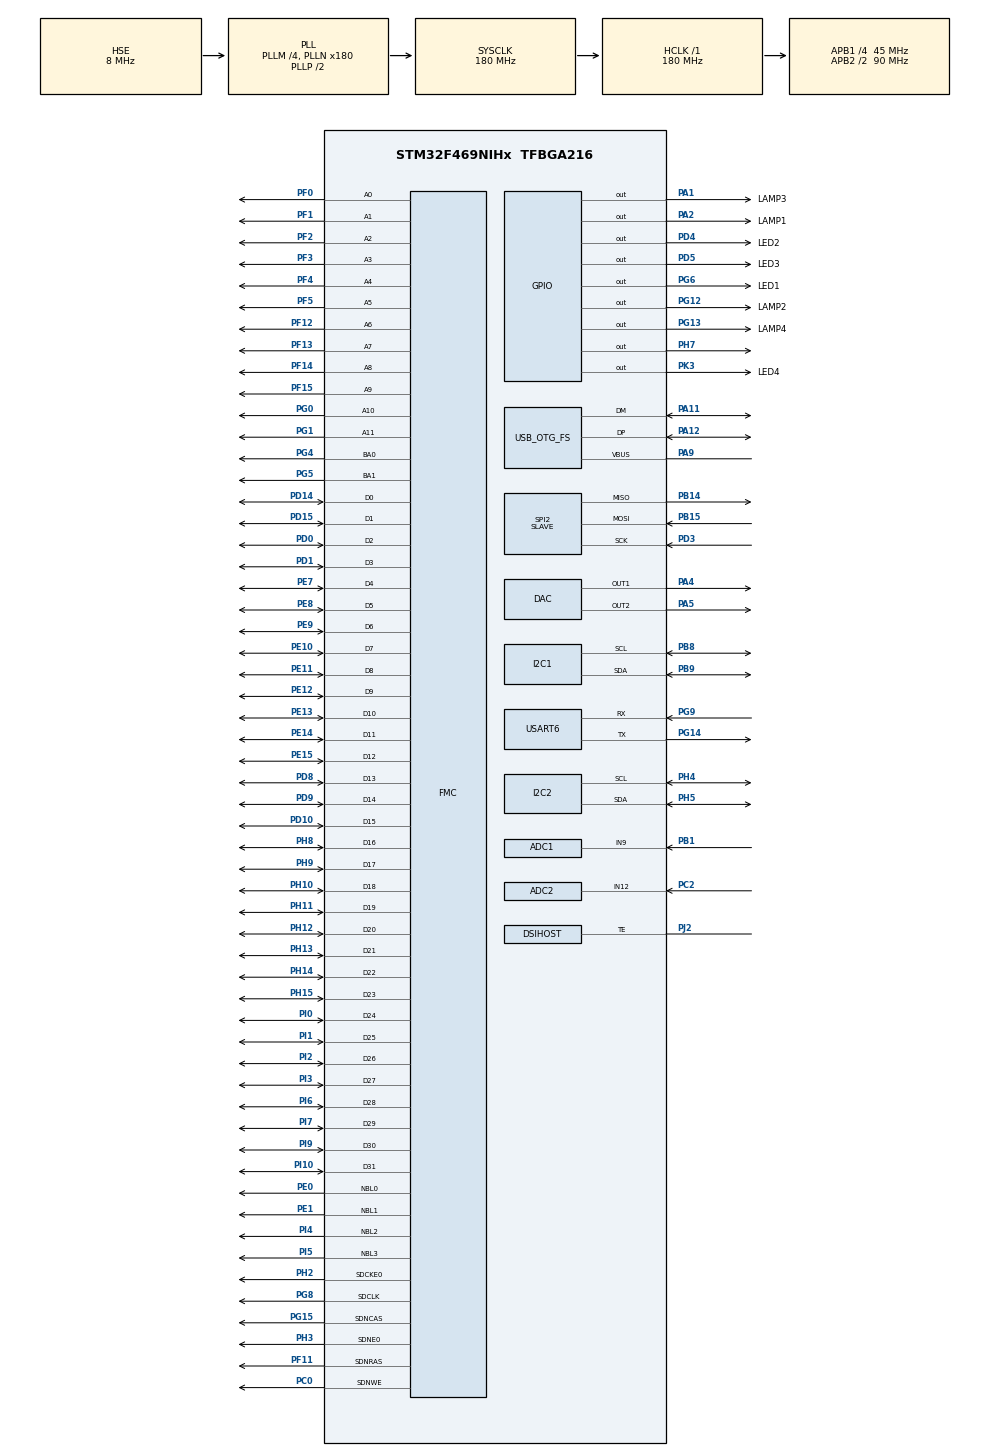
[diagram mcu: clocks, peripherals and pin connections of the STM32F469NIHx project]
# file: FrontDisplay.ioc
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ADC1.Channel-0\#ChannelRegularConversion=ADC_CHANNEL_9
ADC1.ClockPrescaler=ADC_CLOCK_SYNC_PCLK_DIV4
ADC1.ContinuousConvMode=ENABLE
ADC1.DMAContinuousRequests=ENABLE
ADC1.DataAlign=ADC_DATAALIGN_RIGHT
ADC1.DiscontinuousConvMode=DISABLE
ADC1.EOCSelection=ADC_EOC_SINGLE_CONV
ADC1.EnableAnalogWatchDog=false
ADC1.ExternalTrigConv=ADC_SOFTWARE_START
ADC1.ExternalTrigConvEdge=ADC_EXTERNALTRIGCONVEDGE_NONE
ADC1.InjNumberOfConversion=0
ADC1.NbrOfConversion=1
ADC1.NbrOfConversionFlag=1
ADC1.Rank-0\#ChannelRegularConversion=1
ADC1.Resolution=ADC_RESOLUTION_8B
ADC1.SamplingTime-0\#ChannelRegularConversion=ADC_SAMPLETIME_3CYCLES
ADC1.ScanConvMode=DISABLE
ADC1.master=1
ADC2.Channel-4\#ChannelRegularConversion=ADC_CHANNEL_12
ADC2.ClockPrescaler=ADC_CLOCK_SYNC_PCLK_DIV4
ADC2.ContinuousConvMode=DISABLE
ADC2.DMAContinuousRequests=DISABLE
ADC2.DataAlign=ADC_DATAALIGN_RIGHT
ADC2.DiscontinuousConvMode=DISABLE
ADC2.EOCSelection=ADC_EOC_SINGLE_CONV
ADC2.EnableAnalogWatchDog=false
ADC2.ExternalTrigConv=ADC_SOFTWARE_START
ADC2.ExternalTrigConvEdge=ADC_EXTERNALTRIGCONVEDGE_NONE
ADC2.InjNumberOfConversion=0
ADC2.NbrOfConversion=1
ADC2.NbrOfConversionFlag=1
ADC2.Rank-4\#ChannelRegularConversion=1
ADC2.Resolution=ADC_RESOLUTION_8B
ADC2.SamplingTime-4\#ChannelRegularConversion=ADC_SAMPLETIME_3CYCLES
ADC2.ScanConvMode=DISABLE
DAC.DAC_Trigger=DAC_TRIGGER_T4_TRGO
DAC.DAC_Trigger2=DAC_TRIGGER_T4_TRGO
DSIHOST.LPDcsLongWrite=DSI_LP_DLW_ENABLE
DSIHOST.LPDcsShortReadNoP=DSI_LP_DSR0P_ENABLE
DSIHOST.LPDcsShortWriteNoP=DSI_LP_DSW0P_ENABLE
DSIHOST.LPDcsShortWriteOneP=DSI_LP_DSW1P_ENABLE
DSIHOST.LPGenLongWrite=DSI_LP_GLW_ENABLE
DSIHOST.LPGenShortReadNoP=DSI_LP_GSR0P_ENABLE
DSIHOST.LPGenShortReadOneP=DSI_LP_GSR1P_ENABLE
DSIHOST.LPGenShortReadTwoP=DSI_LP_GSR2P_ENABLE
DSIHOST.LPGenShortWriteNoP=DSI_LP_GSW0P_ENABLE
DSIHOST.LPGenShortWriteOneP=DSI_LP_GSW1P_ENABLE
DSIHOST.LPGenShortWriteTwoP=DSI_LP_GSW2P_ENABLE
DSIHOST.LPMaxReadPacket=DSI_LP_MRDP_ENABLE
DSIHOST.NumberOfLanes=DSI_TWO_DATA_LANES
DSIHOST.StopWaitTime=10
DSIHOST.TEAcknowledgeRequest=DSI_TE_ACKNOWLEDGE_ENABLE
DSIHOST_CKN.Mode=DSIHost_Adapted_TE
DSIHOST_CKN.Signal=DSIHOST_CKN
DSIHOST_CKP.Mode=DSIHost_Adapted_TE
DSIHOST_CKP.Signal=DSIHOST_CKP
DSIHOST_D0N.Mode=DSIHost_Adapted_TE
DSIHOST_D0N.Signal=DSIHOST_D0N
DSIHOST_D0P.Mode=DSIHost_Adapted_TE
DSIHOST_D0P.Signal=DSIHOST_D0P
DSIHOST_D1N.Mode=DSIHost_Adapted_TE
DSIHOST_D1N.Signal=DSIHOST_D1N
DSIHOST_D1P.Mode=DSIHost_Adapted_TE
DSIHOST_D1P.Signal=DSIHOST_D1P
Dma.ADC1.2.Direction=DMA_PERIPH_TO_MEMORY
Dma.ADC1.2.FIFOMode=DMA_FIFOMODE_DISABLE
Dma.ADC1.2.Instance=DMA2_Stream0
Dma.ADC1.2.MemDataAlignment=DMA_MDATAALIGN_BYTE
Dma.ADC1.2.MemInc=DMA_MINC_ENABLE
Dma.ADC1.2.Mode=DMA_CIRCULAR
Dma.ADC1.2.PeriphDataAlignment=DMA_PDATAALIGN_BYTE
Dma.ADC1.2.PeriphInc=DMA_PINC_DISABLE
Dma.ADC1.2.Priority=DMA_PRIORITY_LOW
Dma.DAC1.0.Direction=DMA_MEMORY_TO_PERIPH
Dma.DAC1.0.FIFOMode=DMA_FIFOMODE_DISABLE
Dma.DAC1.0.Instance=DMA1_Stream5
Dma.DAC1.0.MemDataAlignment=DMA_MDATAALIGN_BYTE
Dma.DAC1.0.MemInc=DMA_MINC_ENABLE
Dma.DAC1.0.Mode=DMA_CIRCULAR
Dma.DAC1.0.PeriphDataAlignment=DMA_PDATAALIGN_BYTE
Dma.DAC1.0.PeriphInc=DMA_PINC_DISABLE
Dma.DAC1.0.Priority=DMA_PRIORITY_LOW
Dma.DAC2.1.Direction=DMA_MEMORY_TO_PERIPH
Dma.DAC2.1.FIFOMode=DMA_FIFOMODE_DISABLE
Dma.DAC2.1.Instance=DMA1_Stream6
Dma.DAC2.1.MemDataAlignment=DMA_MDATAALIGN_BYTE
Dma.DAC2.1.MemInc=DMA_MINC_ENABLE
Dma.DAC2.1.Mode=DMA_CIRCULAR
Dma.DAC2.1.PeriphDataAlignment=DMA_PDATAALIGN_BYTE
Dma.DAC2.1.PeriphInc=DMA_PINC_DISABLE
Dma.DAC2.1.Priority=DMA_PRIORITY_LOW
Dma.Request0=DAC1
Dma.Request1=DAC2
Dma.Request2=ADC1
Dma.Request3=USART6_RX
Dma.Request4=SPI2_RX
Dma.Request5=SPI2_TX
Dma.SPI2_RX.4.Direction=DMA_PERIPH_TO_MEMORY
Dma.SPI2_RX.4.FIFOMode=DMA_FIFOMODE_DISABLE
Dma.SPI2_RX.4.Instance=DMA1_Stream3
Dma.SPI2_RX.4.MemDataAlignment=DMA_MDATAALIGN_BYTE
Dma.SPI2_RX.4.MemInc=DMA_MINC_ENABLE
Dma.SPI2_RX.4.Mode=DMA_CIRCULAR
Dma.SPI2_RX.4.PeriphDataAlignment=DMA_PDATAALIGN_BYTE
Dma.SPI2_RX.4.PeriphInc=DMA_PINC_DISABLE
Dma.SPI2_RX.4.Priority=DMA_PRIORITY_LOW
Dma.SPI2_TX.5.Direction=DMA_MEMORY_TO_PERIPH
Dma.SPI2_TX.5.FIFOMode=DMA_FIFOMODE_DISABLE
Dma.SPI2_TX.5.Instance=DMA1_Stream4
Dma.SPI2_TX.5.MemDataAlignment=DMA_MDATAALIGN_BYTE
Dma.SPI2_TX.5.MemInc=DMA_MINC_ENABLE
Dma.SPI2_TX.5.Mode=DMA_NORMAL
Dma.SPI2_TX.5.PeriphDataAlignment=DMA_PDATAALIGN_BYTE
Dma.SPI2_TX.5.PeriphInc=DMA_PINC_DISABLE
Dma.SPI2_TX.5.Priority=DMA_PRIORITY_LOW
Dma.USART6_RX.3.Direction=DMA_PERIPH_TO_MEMORY
Dma.USART6_RX.3.FIFOMode=DMA_FIFOMODE_DISABLE
Dma.USART6_RX.3.Instance=DMA2_Stream1
Dma.USART6_RX.3.MemDataAlignment=DMA_MDATAALIGN_BYTE
Dma.USART6_RX.3.MemInc=DMA_MINC_ENABLE
Dma.USART6_RX.3.Mode=DMA_CIRCULAR
Dma.USART6_RX.3.PeriphDataAlignment=DMA_PDATAALIGN_BYTE
Dma.USART6_RX.3.PeriphInc=DMA_PINC_DISABLE
Dma.USART6_RX.3.Priority=DMA_PRIORITY_VERY_HIGH
FMC.CASLatency1=FMC_SDRAM_CAS_LATENCY_3
FMC.ExitSelfRefreshDelay1=7
FMC.LoadToActiveDelay1=2
FMC.RCDDelay1=2
FMC.RPDelay1=2
FMC.RPDelay2=2
FMC.ReadBurst1=FMC_SDRAM_RBURST_ENABLE
FMC.ReadBurst2=FMC_SDRAM_RBURST_ENABLE
FMC.RowCycleDelay1=7
FMC.RowCycleDelay2=7
FMC.SDClockPeriod1=FMC_SDRAM_CLOCK_PERIOD_2
FMC.SDClockPeriod2=FMC_SDRAM_CLOCK_PERIOD_2
FMC.SelfRefreshTime1=4
FMC.WriteRecoveryTime1=3
GRAPHICS.BSP.number=1
GRAPHICS.Check_OTM8009A_PixelFormat-STemWin=1
GRAPHICS.DMA2D_Graphics-STemWin=1
GRAPHICS.EA_1_Apptype=Window
GRAPHICS.EA_1_executable_name-STemWin=GUIBuilder.exe
GRAPHICS.GUI_NUM_LAYERS-STemWin=1
GRAPHICS.LIN_Color_Conversion_Layer0=GUICC_M8888I
GRAPHICS.LIN_Frame_Buffer_Depth_Layer0-STemWin=32
GRAPHICS.Num_MultBuffers=2
GRAPHICS.OPTIM_OS_use-STemWin=4
GRAPHICS.USE_Embedded_Wizard-STemWin=0
GRAPHICS.USE_STTouchGFX-STemWin=0
GRAPHICS.UseGUIBuilder=Enabled
GRAPHICS.Use_SDRAM-STemWin=SDRAM1_BANK1
GRAPHICS.Xsize_PHYS=800
GRAPHICS.Ysize_PHYS=480
GRAPHICS0.BSP.STBoard=false
GRAPHICS0.BSP.api=UnknownBspDriver
GRAPHICS0.BSP.component=GPIO
GRAPHICS0.BSP.i2caddr=0
GRAPHICS0.BSP.i2creg=0
GRAPHICS0.BSP.instance=PH7
GRAPHICS0.BSP.ip=GPIO
GRAPHICS0.BSP.mode=Output
GRAPHICS0.BSP.name=LCD Reset Pin XRES
GRAPHICS0.BSP.solution=PH7
LTDC.ActiveW=400
LTDC.Alpha_L0=255
LTDC.BlendingFactor1_L0=LTDC_BLENDING_FACTOR1_PAxCA
LTDC.BlendingFactor2_L0=LTDC_BLENDING_FACTOR2_PAxCA
LTDC.FBStartAdress_L0=0xC0000000
LTDC.HBP=1
LTDC.HFP=1
LTDC.HSync=1
LTDC.ImageHeight_L0=480
LTDC.ImageWidth_L0=400
LTDC.Layers=0
LTDC.VBP=1
LTDC.VFP=1
LTDC.VSync=1
LTDC.WindowX1_L0=400
LTDC.WindowY1_L0=480
Mcu.Family=STM32F4
Mcu.Name=STM32F469NIHx
Mcu.Package=TFBGA216
NVIC.DMA1_Stream3_IRQn=true\:0\:0\:false\:false\:true\:false
NVIC.DMA1_Stream4_IRQn=true\:0\:0\:false\:false\:true\:false
NVIC.DMA1_Stream5_IRQn=true\:0\:0\:false\:false\:true\:false
NVIC.DMA1_Stream6_IRQn=true\:0\:0\:false\:false\:true\:false
NVIC.DMA2D_IRQn=true\:15\:0\:true\:false\:true\:true
NVIC.DMA2_Stream0_IRQn=true\:0\:0\:false\:false\:true\:false
NVIC.DMA2_Stream1_IRQn=true\:0\:0\:false\:false\:true\:false
NVIC.DSI_IRQn=true\:15\:0\:true\:false\:true\:true
NVIC.LTDC_IRQn=true\:15\:0\:true\:false\:true\:true
NVIC.OTG_FS_IRQn=true\:0\:0\:false\:false\:true\:false
NVIC.PriorityGroup=NVIC_PRIORITYGROUP_4
NVIC.SPI2_IRQn=true\:0\:0\:false\:false\:true\:true
NVIC.TIM3_IRQn=true\:1\:0\:true\:false\:true\:true
NVIC.TIM4_IRQn=true\:0\:0\:false\:false\:true\:true
NVIC.USART6_IRQn=true\:0\:0\:false\:false\:true\:true
PA1.GPIO_Label=LAMP3
PA1.Signal=GPIO_Output
PA11.Mode=Device_Only
PA11.Signal=USB_OTG_FS_DM
PA12.Mode=Device_Only
PA12.Signal=USB_OTG_FS_DP
PA2.GPIO_Label=LAMP1
PA2.Signal=GPIO_Output
PA4.Signal=COMP_DAC1_group
PA5.Signal=COMP_DAC2_group
PA9.Mode=Activate_VBUS
PA9.Signal=USB_OTG_FS_VBUS
PB1.Signal=ADCx_IN9
PB14.Mode=Full_Duplex_Slave
PB14.Signal=SPI2_MISO
PB15.Mode=Full_Duplex_Slave
PB15.Signal=SPI2_MOSI
PB8.Mode=I2C
PB8.Signal=I2C1_SCL
PB9.Mode=I2C
PB9.Signal=I2C1_SDA
PC0.Signal=FMC_SDNWE
PC2.Signal=ADCx_IN12
PD0.Signal=FMC_D2_DA2
PD1.Signal=FMC_D3_DA3
PD10.Signal=FMC_D15_DA15
PD14.Signal=FMC_D0_DA0
PD15.Signal=FMC_D1_DA1
PD3.Mode=Full_Duplex_Slave
PD3.Signal=SPI2_SCK
PD4.GPIO_Label=LED2
PD4.Signal=GPIO_Output
PD5.GPIO_Label=LED3
PD5.Signal=GPIO_Output
PD8.Signal=FMC_D13_DA13
PD9.Signal=FMC_D14_DA14
PE0.Signal=FMC_NBL0
PE1.Signal=FMC_NBL1
PE10.Signal=FMC_D7_DA7
PE11.Signal=FMC_D8_DA8
PE12.Signal=FMC_D9_DA9
PE13.Signal=FMC_D10_DA10
PE14.Signal=FMC_D11_DA11
PE15.Signal=FMC_D12_DA12
PE7.Signal=FMC_D4_DA4
PE8.Signal=FMC_D5_DA5
PE9.Signal=FMC_D6_DA6
PF0.Signal=FMC_A0
PF1.Signal=FMC_A1
PF11.Signal=FMC_SDNRAS
PF12.Signal=FMC_A6
PF13.Signal=FMC_A7
PF14.Signal=FMC_A8
PF15.Signal=FMC_A9
PF2.Signal=FMC_A2
PF3.Signal=FMC_A3
PF4.Signal=FMC_A4
PF5.Signal=FMC_A5
PG0.Signal=FMC_A10
PG1.Signal=FMC_A11
PG12.GPIO_Label=LAMP2
PG12.Signal=GPIO_Output
PG13.GPIO_Label=LAMP4
PG13.Signal=GPIO_Output
PG14.Mode=Asynchronous
PG14.Signal=USART6_TX
PG15.Signal=FMC_SDNCAS
PG4.Signal=FMC_A14_BA0
PG5.Signal=FMC_A15_BA1
PG6.GPIO_Label=LED1
PG6.Signal=GPIO_Output
PG8.Signal=FMC_SDCLK
PG9.Mode=Asynchronous
PG9.Signal=USART6_RX
PH0/OSC_IN.Mode=HSE-External-Oscillator
PH0/OSC_IN.Signal=RCC_OSC_IN
PH1/OSC_OUT.Mode=HSE-External-Oscillator
PH1/OSC_OUT.Signal=RCC_OSC_OUT
PH10.Signal=FMC_D18
PH11.Signal=FMC_D19
PH12.Signal=FMC_D20
PH13.Signal=FMC_D21
PH14.Signal=FMC_D22
PH15.Signal=FMC_D23
PH2.Mode=SdramChipSelect1_1
PH2.Signal=FMC_SDCKE0
PH3.Mode=SdramChipSelect1_1
PH3.Signal=FMC_SDNE0
PH4.Mode=I2C
PH4.Signal=I2C2_SCL
PH5.Mode=I2C
PH5.Signal=I2C2_SDA
PH7.Signal=GPIO_Output
PH8.Signal=FMC_D16
PH9.Signal=FMC_D17
PI0.Signal=FMC_D24
PI1.Signal=FMC_D25
PI10.Signal=FMC_D31
PI2.Signal=FMC_D26
PI3.Signal=FMC_D27
PI4.Signal=FMC_NBL2
PI5.Signal=FMC_NBL3
PI6.Signal=FMC_D28
PI7.Signal=FMC_D29
PI9.Signal=FMC_D30
PJ2.Mode=DSIHost_Adapted_TE
PJ2.Signal=DSIHOST_TE
PK3.GPIO_Label=LED4
PK3.Signal=GPIO_Output
ProjectManager.HeapSize=0x500
ProjectManager.StackSize=0x800
ProjectManager.TargetToolchain=SW4STM32
RCC.AHBFreq_Value=180000000
RCC.APB1CLKDivider=RCC_HCLK_DIV4
RCC.APB1Freq_Value=45000000
RCC.APB1TimFreq_Value=90000000
RCC.APB2CLKDivider=RCC_HCLK_DIV2
RCC.APB2Freq_Value=90000000
RCC.APB2TimFreq_Value=180000000
RCC.CortexFreq_Value=180000000
RCC.HCLKFreq_Value=180000000
RCC.HSE_VALUE=8000000
RCC.PLLDSIIDF=DSI_PLL_IN_DIV2
RCC.PLLDSINDIV=125
RCC.PLLM=4
RCC.PLLN=180
RCC.PLLQ=8
RCC.PLLSAIN=96
RCC.PLLSAIP=RCC_PLLSAIP_DIV4
RCC.PLLSAIRDiv=RCC_PLLSAIDIVR_4
RCC.PLLSourceVirtual=RCC_PLLSOURCE_HSE
RCC.SYSCLKFreq_VALUE=180000000
RCC.SYSCLKSource=RCC_SYSCLKSOURCE_PLLCLK
RCC.USBCLockSelection=RCC_CLK48CLKSOURCE_PLLSAIP
RCC.USBFreq_Value=48000000
RCC.VCOOutputFreq_Value=360000000
SH.ADCx_IN12.0=ADC2_IN12,IN12
SH.ADCx_IN9.0=ADC1_IN9,IN9
SH.COMP_DAC1_group.0=DAC_OUT1,DAC_OUT1
SH.COMP_DAC2_group.0=DAC_OUT2,DAC_OUT2
SH.FMC_A0.0=FMC_A0,12b-sda1
SH.FMC_A1.0=FMC_A1,12b-sda1
SH.FMC_A10.0=FMC_A10,12b-sda1
SH.FMC_A11.0=FMC_A11,12b-sda1
SH.FMC_A14_BA0.0=FMC_BA0,FourSdramBanks1
SH.FMC_A15_BA1.0=FMC_BA1,FourSdramBanks1
SH.FMC_A2.0=FMC_A2,12b-sda1
SH.FMC_A3.0=FMC_A3,12b-sda1
SH.FMC_A4.0=FMC_A4,12b-sda1
SH.FMC_A5.0=FMC_A5,12b-sda1
SH.FMC_A6.0=FMC_A6,12b-sda1
SH.FMC_A7.0=FMC_A7,12b-sda1
SH.FMC_A8.0=FMC_A8,12b-sda1
SH.FMC_A9.0=FMC_A9,12b-sda1
SH.FMC_D0_DA0.0=FMC_D0,sd-32b-d1
SH.FMC_D10_DA10.0=FMC_D10,sd-32b-d1
SH.FMC_D11_DA11.0=FMC_D11,sd-32b-d1
SH.FMC_D12_DA12.0=FMC_D12,sd-32b-d1
SH.FMC_D13_DA13.0=FMC_D13,sd-32b-d1
SH.FMC_D14_DA14.0=FMC_D14,sd-32b-d1
SH.FMC_D15_DA15.0=FMC_D15,sd-32b-d1
SH.FMC_D16.0=FMC_D16,sd-32b-d1
SH.FMC_D17.0=FMC_D17,sd-32b-d1
SH.FMC_D18.0=FMC_D18,sd-32b-d1
SH.FMC_D19.0=FMC_D19,sd-32b-d1
SH.FMC_D1_DA1.0=FMC_D1,sd-32b-d1
SH.FMC_D20.0=FMC_D20,sd-32b-d1
SH.FMC_D21.0=FMC_D21,sd-32b-d1
SH.FMC_D22.0=FMC_D22,sd-32b-d1
SH.FMC_D23.0=FMC_D23,sd-32b-d1
SH.FMC_D24.0=FMC_D24,sd-32b-d1
SH.FMC_D25.0=FMC_D25,sd-32b-d1
SH.FMC_D26.0=FMC_D26,sd-32b-d1
SH.FMC_D27.0=FMC_D27,sd-32b-d1
SH.FMC_D28.0=FMC_D28,sd-32b-d1
SH.FMC_D29.0=FMC_D29,sd-32b-d1
SH.FMC_D2_DA2.0=FMC_D2,sd-32b-d1
SH.FMC_D30.0=FMC_D30,sd-32b-d1
SH.FMC_D31.0=FMC_D31,sd-32b-d1
SH.FMC_D3_DA3.0=FMC_D3,sd-32b-d1
SH.FMC_D4_DA4.0=FMC_D4,sd-32b-d1
SH.FMC_D5_DA5.0=FMC_D5,sd-32b-d1
SH.FMC_D6_DA6.0=FMC_D6,sd-32b-d1
SH.FMC_D7_DA7.0=FMC_D7,sd-32b-d1
SH.FMC_D8_DA8.0=FMC_D8,sd-32b-d1
SH.FMC_D9_DA9.0=FMC_D9,sd-32b-d1
SH.FMC_NBL0.0=FMC_NBL0,Sd4ByteEnable1
SH.FMC_NBL1.0=FMC_NBL1,Sd4ByteEnable1
SH.FMC_NBL2.0=FMC_NBL2,Sd4ByteEnable1
SH.FMC_NBL3.0=FMC_NBL3,Sd4ByteEnable1
SH.FMC_SDCLK.0=FMC_SDCLK,12b-sda1
SH.FMC_SDNCAS.0=FMC_SDNCAS,12b-sda1
SH.FMC_SDNRAS.0=FMC_SDNRAS,12b-sda1
SH.FMC_SDNWE.0=FMC_SDNWE,12b-sda1
SPI2.Direction=SPI_DIRECTION_2LINES
SPI2.Mode=SPI_MODE_SLAVE
SPI2.VirtualType=VM_SLAVE
TIM3.Period=499
TIM3.Prescaler=8999
TIM4.Period=1000
TIM4.TIM_MasterOutputTrigger=TIM_TRGO_UPDATE
USART6.VirtualMode=VM_ASYNC
USB_DEVICE.CLASS_NAME_FS=CDC
USB_DEVICE.VirtualMode-CDC_FS=Cdc
USB_DEVICE.VirtualModeFS=Cdc_FS
USB_OTG_FS.VirtualMode=Device_Only
VP_CRC_VS_CRC.Mode=CRC_Activate
VP_DMA2D_VS_DMA2D.Mode=DMA2D_Activate
VP_GRAPHICS_VS-DisplayInterface-DSI-LTDC.Mode=Display Serial Interface using LTDC-DSIHOST
VP_GRAPHICS_VS-STemWin.Mode=STemWin
VP_LTDC_DSIMode.Mode=RGB888
VP_TIM3_VS_ClockSourceITR.Mode=TriggerSource_ITR0
VP_TIM3_VS_ControllerModeReset.Mode=Reset Mode
VP_TIM4_VS_ClockSourceINT.Mode=Internal
VP_USB_DEVICE_VS_USB_DEVICE_CDC_FS.Mode=CDC_FS
board=FrontDisplay

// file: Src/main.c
/**
  ******************************************************************************
  * @file           : main.c
  * @brief          : Main program body
  ******************************************************************************
  * This notice applies to any and all portions of this file
  * that are not between comment pairs USER CODE BEGIN and
  * USER CODE END. Other portions of this file, whether
  * inserted by the user or by software development tools
  * are owned by their respective copyright owners.
  *
  * Copyright (c) 2020 STMicroelectronics International N.V.
  * All rights reserved.
  *
  * Redistribution and use in source and binary forms, with or without
  * modification, are permitted, provided that the following conditions are met:
  *
  * 1. Redistribution of source code must retain the above copyright notice,
  *    this list of conditions and the following disclaimer.
  * 2. Redistributions in binary form must reproduce the above copyright notice,
  *    this list of conditions and the following disclaimer in the documentation
  *    and/or other materials provided with the distribution.
  * 3. Neither the name of STMicroelectronics nor the names of other
  *    contributors to this software may be used to endorse or promote products
  *    derived from this software without specific written permission.
  * 4. This software, including modifications and/or derivative works of this
  *    software, must execute solely and exclusively on microcontroller or
  *    microprocessor devices manufactured by or for STMicroelectronics.
  * 5. Redistribution and use of this software other than as permitted under
  *    this license is void and will automatically terminate your rights under
  *    this license.
  *
  * THIS SOFTWARE IS PROVIDED BY STMICROELECTRONICS AND CONTRIBUTORS "AS IS"
  * AND ANY EXPRESS, IMPLIED OR STATUTORY WARRANTIES, INCLUDING, BUT NOT
  * LIMITED TO, THE IMPLIED WARRANTIES OF MERCHANTABILITY, FITNESS FOR A
  * PARTICULAR PURPOSE AND NON-INFRINGEMENT OF THIRD PARTY INTELLECTUAL PROPERTY
  * RIGHTS ARE DISCLAIMED TO THE FULLEST EXTENT PERMITTED BY LAW. IN NO EVENT
  * SHALL STMICROELECTRONICS OR CONTRIBUTORS BE LIABLE FOR ANY DIRECT, INDIRECT,
  * INCIDENTAL, SPECIAL, EXEMPLARY, OR CONSEQUENTIAL DAMAGES (INCLUDING, BUT NOT
  * LIMITED TO, PROCUREMENT OF SUBSTITUTE GOODS OR SERVICES; LOSS OF USE, DATA,
  * OR PROFITS; OR BUSINESS INTERRUPTION) HOWEVER CAUSED AND ON ANY THEORY OF
  * LIABILITY, WHETHER IN CONTRACT, STRICT LIABILITY, OR TORT (INCLUDING
  * NEGLIGENCE OR OTHERWISE) ARISING IN ANY WAY OUT OF THE USE OF THIS SOFTWARE,
  * EVEN IF ADVISED OF THE POSSIBILITY OF SUCH DAMAGE.
  *
  ******************************************************************************
  */
#include "main.h"
#include "stm32f4xx_hal.h"
#include "usb_device.h"

ADC_HandleTypeDef hadc1;
ADC_HandleTypeDef hadc2;
DMA_HandleTypeDef hdma_adc1;

CRC_HandleTypeDef hcrc;

DAC_HandleTypeDef hdac;
DMA_HandleTypeDef hdma_dac1;
DMA_HandleTypeDef hdma_dac2;

I2C_HandleTypeDef hi2c1;
I2C_HandleTypeDef hi2c2;

SPI_HandleTypeDef hspi2;
DMA_HandleTypeDef hdma_spi2_rx;
DMA_HandleTypeDef hdma_spi2_tx;

TIM_HandleTypeDef htim3;
TIM_HandleTypeDef htim4;

UART_HandleTypeDef huart6;
DMA_HandleTypeDef hdma_usart6_rx;
DMA_HandleTypeDef hdma_usart6_tx;

/* USER CODE BEGIN PV */
/* Private variables ---------------------------------------------------------*/
/* USER CODE END PV */

void SystemClock_Config(void);
static void MX_GPIO_Init(void);
static void MX_DMA_Init(void);
static void MX_I2C1_Init(void);
static void MX_TIM3_Init(void);
static void MX_CRC_Init(void);
extern void GRAPHICS_HW_Init(void);
extern void GRAPHICS_Init(void);
extern void GRAPHICS_MainTask(void);
static void MX_ADC1_Init(void);
static void MX_ADC2_Init(void);
static void MX_DAC_Init(void);
static void MX_TIM4_Init(void);
static void MX_I2C2_Init(void);
static void MX_USART6_UART_Init(void);
static void MX_SPI2_Init(void);

/* USER CODE BEGIN PFP */

/* Private function prototypes -----------------------------------------------*/
void Encoder_Init(void);
/* USER CODE END PFP */

/* USER CODE BEGIN 0 */

uint8_t i2c[17];
uint16_t EncoderAdr[6] = {0,8,16,32,64,128};

uint8_t adresses[255];

int Test=12;
int test;
uint32_t DMA_TRANSFER[250];
char UART_RECIVE[50];

/* USER CODE END 0 */

int main(void)
{

  /* MCU Configuration----------------------------------------------------------*/

  /* Reset of all peripherals, Initializes the Flash interface and the Systick. */
  HAL_Init();

  /* Configure the system clock */
  SystemClock_Config();

  /* Initialize all configured peripherals */
  MX_GPIO_Init();
  MX_DMA_Init();
  MX_I2C1_Init();
  MX_TIM3_Init();
  MX_CRC_Init();
  MX_USB_DEVICE_Init();
  MX_ADC1_Init();
  MX_ADC2_Init();
  MX_DAC_Init();
  MX_TIM4_Init();
  MX_I2C2_Init();
  MX_USART6_UART_Init();
  MX_SPI2_Init();
  /* USER CODE BEGIN 2 */
  Encoder_Init();
  BSP_LED_Init(LED1);
  BSP_LED_Init(LED2);
  BSP_LED_Init(LED3);
  BSP_LED_Init(LED4);

/*

  for (int i = 0; i < 255; i++){
	 if(HAL_I2C_IsDeviceReady(&hi2c1, i,5,10) == HAL_OK) {
		 adresses [i] = 1;
	 }
	 else {
		 adresses [i] = 0;
	 }
    }
*/
  /* USER CODE END 2 */

/* Initialise the graphical hardware */
  GRAPHICS_HW_Init();
  BSP_TS_Init(800, 480);
  HAL_UART_Receive_DMA(&huart6, UART_RECIVE,50);
  HAL_UART_Transmit_DMA(&huart6, UART_TRANSFER,50);
  /* Initialise the graphical stack engine */
  GRAPHICS_Init();

  /* Graphic application */
  GRAPHICS_MainTask();

  /* Infinite loop */
  for(;;);

}

void SystemClock_Config(void)
{

  RCC_OscInitTypeDef RCC_OscInitStruct;
  RCC_ClkInitTypeDef RCC_ClkInitStruct;
  RCC_PeriphCLKInitTypeDef PeriphClkInitStruct;

    /**Configure the main internal regulator output voltage
    */
  __HAL_RCC_PWR_CLK_ENABLE();

  __HAL_PWR_VOLTAGESCALING_CONFIG(PWR_REGULATOR_VOLTAGE_SCALE1);

    /**Initializes the CPU, AHB and APB busses clocks
    */
  RCC_OscInitStruct.OscillatorType = RCC_OSCILLATORTYPE_HSE;
  RCC_OscInitStruct.HSEState = RCC_HSE_ON;
  RCC_OscInitStruct.PLL.PLLState = RCC_PLL_ON;
  RCC_OscInitStruct.PLL.PLLSource = RCC_PLLSOURCE_HSE;
  RCC_OscInitStruct.PLL.PLLM = 4;
  RCC_OscInitStruct.PLL.PLLN = 180;
  RCC_OscInitStruct.PLL.PLLP = RCC_PLLP_DIV2;
  RCC_OscInitStruct.PLL.PLLQ = 8;
  RCC_OscInitStruct.PLL.PLLR = 2;
  if (HAL_RCC_OscConfig(&RCC_OscInitStruct) != HAL_OK)
  {
    _Error_Handler(__FILE__, __LINE__);
  }

    /**Activate the Over-Drive mode
    */
  if (HAL_PWREx_EnableOverDrive() != HAL_OK)
  {
    _Error_Handler(__FILE__, __LINE__);
  }

    /**Initializes the CPU, AHB and APB busses clocks
    */
  RCC_ClkInitStruct.ClockType = RCC_CLOCKTYPE_HCLK|RCC_CLOCKTYPE_SYSCLK
                              |RCC_CLOCKTYPE_PCLK1|RCC_CLOCKTYPE_PCLK2;
  RCC_ClkInitStruct.SYSCLKSource = RCC_SYSCLKSOURCE_PLLCLK;
  RCC_ClkInitStruct.AHBCLKDivider = RCC_SYSCLK_DIV1;
  RCC_ClkInitStruct.APB1CLKDivider = RCC_HCLK_DIV4;
  RCC_ClkInitStruct.APB2CLKDivider = RCC_HCLK_DIV2;

  if (HAL_RCC_ClockConfig(&RCC_ClkInitStruct, FLASH_LATENCY_5) != HAL_OK)
  {
    _Error_Handler(__FILE__, __LINE__);
  }

  PeriphClkInitStruct.PeriphClockSelection = RCC_PERIPHCLK_CLK48|RCC_PERIPHCLK_LTDC;
  PeriphClkInitStruct.PLLSAI.PLLSAIN = 96;
  PeriphClkInitStruct.PLLSAI.PLLSAIR = 2;
  PeriphClkInitStruct.PLLSAI.PLLSAIP = RCC_PLLSAIP_DIV4;
  PeriphClkInitStruct.PLLSAIDivR = RCC_PLLSAIDIVR_4;
  PeriphClkInitStruct.Clk48ClockSelection = RCC_CLK48CLKSOURCE_PLLSAIP;
  if (HAL_RCCEx_PeriphCLKConfig(&PeriphClkInitStruct) != HAL_OK)
  {
    _Error_Handler(__FILE__, __LINE__);
  }

    /**Configure the Systick interrupt time
    */
  HAL_SYSTICK_Config(HAL_RCC_GetHCLKFreq()/1000);

    /**Configure the Systick
    */
  HAL_SYSTICK_CLKSourceConfig(SYSTICK_CLKSOURCE_HCLK);

  /* SysTick_IRQn interrupt configuration */
  HAL_NVIC_SetPriority(SysTick_IRQn, 0, 0);
}

/* ADC1 init function */
static void MX_ADC1_Init(void)
{

  ADC_ChannelConfTypeDef sConfig;

    /**Configure the global features of the ADC (Clock, Resolution, Data Alignment and number of conversion)
    */
  hadc1.Instance = ADC1;
  hadc1.Init.ClockPrescaler = ADC_CLOCK_SYNC_PCLK_DIV4;
  hadc1.Init.Resolution = ADC_RESOLUTION_8B;
  hadc1.Init.ScanConvMode = DISABLE;
  hadc1.Init.ContinuousConvMode = ENABLE;
  hadc1.Init.DiscontinuousConvMode = DISABLE;
  hadc1.Init.ExternalTrigConvEdge = ADC_EXTERNALTRIGCONVEDGE_NONE;
  hadc1.Init.ExternalTrigConv = ADC_SOFTWARE_START;
  hadc1.Init.DataAlign = ADC_DATAALIGN_RIGHT;
  hadc1.Init.NbrOfConversion = 1;
  hadc1.Init.DMAContinuousRequests = ENABLE;
  hadc1.Init.EOCSelection = ADC_EOC_SINGLE_CONV;
  if (HAL_ADC_Init(&hadc1) != HAL_OK)
  {
    _Error_Handler(__FILE__, __LINE__);
  }

    /**Configure for the selected ADC regular channel its corresponding rank in the sequencer and its sample time.
    */
  sConfig.Channel = ADC_CHANNEL_9;
  sConfig.Rank = 1;
  sConfig.SamplingTime = ADC_SAMPLETIME_3CYCLES;
  if (HAL_ADC_ConfigChannel(&hadc1, &sConfig) != HAL_OK)
  {
    _Error_Handler(__FILE__, __LINE__);
  }

}

/* ADC2 init function */
static void MX_ADC2_Init(void)
{

  ADC_ChannelConfTypeDef sConfig;

    /**Configure the global features of the ADC (Clock, Resolution, Data Alignment and number of conversion)
    */
  hadc2.Instance = ADC2;
  hadc2.Init.ClockPrescaler = ADC_CLOCK_SYNC_PCLK_DIV4;
  hadc2.Init.Resolution = ADC_RESOLUTION_8B;
  hadc2.Init.ScanConvMode = DISABLE;
  hadc2.Init.ContinuousConvMode = DISABLE;
  hadc2.Init.DiscontinuousConvMode = DISABLE;
  hadc2.Init.ExternalTrigConvEdge = ADC_EXTERNALTRIGCONVEDGE_NONE;
  hadc2.Init.ExternalTrigConv = ADC_SOFTWARE_START;
  hadc2.Init.DataAlign = ADC_DATAALIGN_RIGHT;
  hadc2.Init.NbrOfConversion = 1;
  hadc2.Init.DMAContinuousRequests = DISABLE;
  hadc2.Init.EOCSelection = ADC_EOC_SINGLE_CONV;
  if (HAL_ADC_Init(&hadc2) != HAL_OK)
  {
    _Error_Handler(__FILE__, __LINE__);
  }

    /**Configure for the selected ADC regular channel its corresponding rank in the sequencer and its sample time.
    */
  sConfig.Channel = ADC_CHANNEL_12;
  sConfig.Rank = 1;
  sConfig.SamplingTime = ADC_SAMPLETIME_3CYCLES;
  if (HAL_ADC_ConfigChannel(&hadc2, &sConfig) != HAL_OK)
  {
    _Error_Handler(__FILE__, __LINE__);
  }

}

/* CRC init function */
static void MX_CRC_Init(void)
{

  hcrc.Instance = CRC;
  if (HAL_CRC_Init(&hcrc) != HAL_OK)
  {
    _Error_Handler(__FILE__, __LINE__);
  }

}

/* DAC init function */
static void MX_DAC_Init(void)
{

  DAC_ChannelConfTypeDef sConfig;

    /**DAC Initialization
    */
  hdac.Instance = DAC;
  if (HAL_DAC_Init(&hdac) != HAL_OK)
  {
    _Error_Handler(__FILE__, __LINE__);
  }

    /**DAC channel OUT1 config
    */
  sConfig.DAC_Trigger = DAC_TRIGGER_T4_TRGO;
  sConfig.DAC_OutputBuffer = DAC_OUTPUTBUFFER_ENABLE;
  if (HAL_DAC_ConfigChannel(&hdac, &sConfig, DAC_CHANNEL_1) != HAL_OK)
  {
    _Error_Handler(__FILE__, __LINE__);
  }

    /**DAC channel OUT2 config
    */
  if (HAL_DAC_ConfigChannel(&hdac, &sConfig, DAC_CHANNEL_2) != HAL_OK)
  {
    _Error_Handler(__FILE__, __LINE__);
  }

}

/* I2C1 init function */
static void MX_I2C1_Init(void)
{

  hi2c1.Instance = I2C1;
  hi2c1.Init.ClockSpeed = 100000;
  hi2c1.Init.DutyCycle = I2C_DUTYCYCLE_2;
  hi2c1.Init.OwnAddress1 = 0;
  hi2c1.Init.AddressingMode = I2C_ADDRESSINGMODE_7BIT;
  hi2c1.Init.DualAddressMode = I2C_DUALADDRESS_DISABLE;
  hi2c1.Init.OwnAddress2 = 0;
  hi2c1.Init.GeneralCallMode = I2C_GENERALCALL_DISABLE;
  hi2c1.Init.NoStretchMode = I2C_NOSTRETCH_DISABLE;
  if (HAL_I2C_Init(&hi2c1) != HAL_OK)
  {
    _Error_Handler(__FILE__, __LINE__);
  }

}

/* I2C2 init function */
static void MX_I2C2_Init(void)
{

  hi2c2.Instance = I2C2;
  hi2c2.Init.ClockSpeed = 100000;
  hi2c2.Init.DutyCycle = I2C_DUTYCYCLE_2;
  hi2c2.Init.OwnAddress1 = 0;
  hi2c2.Init.AddressingMode = I2C_ADDRESSINGMODE_7BIT;
  hi2c2.Init.DualAddressMode = I2C_DUALADDRESS_DISABLE;
  hi2c2.Init.OwnAddress2 = 0;
  hi2c2.Init.GeneralCallMode = I2C_GENERALCALL_DISABLE;
  hi2c2.Init.NoStretchMode = I2C_NOSTRETCH_DISABLE;
  if (HAL_I2C_Init(&hi2c2) != HAL_OK)
  {
    _Error_Handler(__FILE__, __LINE__);
  }

}

/* SPI2 init function */
static void MX_SPI2_Init(void)
{

  /* SPI2 parameter configuration*/
  hspi2.Instance = SPI2;
  hspi2.Init.Mode = SPI_MODE_SLAVE;
  hspi2.Init.Direction = SPI_DIRECTION_2LINES;
  hspi2.Init.DataSize = SPI_DATASIZE_8BIT;
  hspi2.Init.CLKPolarity = SPI_POLARITY_LOW;
  hspi2.Init.CLKPhase = SPI_PHASE_1EDGE;
  hspi2.Init.NSS = SPI_NSS_SOFT;
  hspi2.Init.FirstBit = SPI_FIRSTBIT_MSB;
  hspi2.Init.TIMode = SPI_TIMODE_DISABLE;
  hspi2.Init.CRCCalculation = SPI_CRCCALCULATION_DISABLE;
  hspi2.Init.CRCPolynomial = 10;
  if (HAL_SPI_Init(&hspi2) != HAL_OK)
  {
    _Error_Handler(__FILE__, __LINE__);
  }

}

/* TIM3 init function */
static void MX_TIM3_Init(void)
{

  TIM_SlaveConfigTypeDef sSlaveConfig;
  TIM_MasterConfigTypeDef sMasterConfig;

  htim3.Instance = TIM3;
  htim3.Init.Prescaler = 8999;
  htim3.Init.CounterMode = TIM_COUNTERMODE_UP;
  htim3.Init.Period = 499;
  htim3.Init.ClockDivision = TIM_CLOCKDIVISION_DIV1;
  if (HAL_TIM_Base_Init(&htim3) != HAL_OK)
  {
    _Error_Handler(__FILE__, __LINE__);
  }

  sSlaveConfig.SlaveMode = TIM_SLAVEMODE_RESET;
  sSlaveConfig.InputTrigger = TIM_TS_ITR0;
  if (HAL_TIM_SlaveConfigSynchronization(&htim3, &sSlaveConfig) != HAL_OK)
  {
    _Error_Handler(__FILE__, __LINE__);
  }

  sMasterConfig.MasterOutputTrigger = TIM_TRGO_RESET;
  sMasterConfig.MasterSlaveMode = TIM_MASTERSLAVEMODE_DISABLE;
  if (HAL_TIMEx_MasterConfigSynchronization(&htim3, &sMasterConfig) != HAL_OK)
  {
    _Error_Handler(__FILE__, __LINE__);
  }

}

/* TIM4 init function */
static void MX_TIM4_Init(void)
{

  TIM_ClockConfigTypeDef sClockSourceConfig;
  TIM_MasterConfigTypeDef sMasterConfig;

  htim4.Instance = TIM4;
  htim4.Init.Prescaler = 0;
  htim4.Init.CounterMode = TIM_COUNTERMODE_UP;
  htim4.Init.Period = 1000;
  htim4.Init.ClockDivision = TIM_CLOCKDIVISION_DIV1;
  if (HAL_TIM_Base_Init(&htim4) != HAL_OK)
  {
    _Error_Handler(__FILE__, __LINE__);
  }

  sClockSourceConfig.ClockSource = TIM_CLOCKSOURCE_INTERNAL;
  if (HAL_TIM_ConfigClockSource(&htim4, &sClockSourceConfig) != HAL_OK)
  {
    _Error_Handler(__FILE__, __LINE__);
  }

  sMasterConfig.MasterOutputTrigger = TIM_TRGO_UPDATE;
  sMasterConfig.MasterSlaveMode = TIM_MASTERSLAVEMODE_DISABLE;
  if (HAL_TIMEx_MasterConfigSynchronization(&htim4, &sMasterConfig) != HAL_OK)
  {
    _Error_Handler(__FILE__, __LINE__);
  }

}

/* USART6 init function */
static void MX_USART6_UART_Init(void)
{

  huart6.Instance = USART6;
  huart6.Init.BaudRate = 19200;
  huart6.Init.WordLength = UART_WORDLENGTH_8B;
  huart6.Init.StopBits = UART_STOPBITS_1;
  huart6.Init.Parity = UART_PARITY_NONE;
  huart6.Init.Mode = UART_MODE_TX_RX;
  huart6.Init.HwFlowCtl = UART_HWCONTROL_NONE;
  huart6.Init.OverSampling = UART_OVERSAMPLING_16;
  if (HAL_UART_Init(&huart6) != HAL_OK)
  {
    _Error_Handler(__FILE__, __LINE__);
  }

}

static void MX_DMA_Init(void)
{
  /* DMA controller clock enable */
  __HAL_RCC_DMA1_CLK_ENABLE();
  __HAL_RCC_DMA2_CLK_ENABLE();

  /* DMA interrupt init */
  /* DMA1_Stream3_IRQn interrupt configuration */
  HAL_NVIC_SetPriority(DMA1_Stream3_IRQn, 0, 0);
  HAL_NVIC_EnableIRQ(DMA1_Stream3_IRQn);
  /* DMA1_Stream4_IRQn interrupt configuration */
  HAL_NVIC_SetPriority(DMA1_Stream4_IRQn, 0, 0);
  HAL_NVIC_EnableIRQ(DMA1_Stream4_IRQn);
  /* DMA1_Stream5_IRQn interrupt configuration */
  HAL_NVIC_SetPriority(DMA1_Stream5_IRQn, 0, 0);
  HAL_NVIC_EnableIRQ(DMA1_Stream5_IRQn);
  /* DMA1_Stream6_IRQn interrupt configuration */
  HAL_NVIC_SetPriority(DMA1_Stream6_IRQn, 0, 0);
  HAL_NVIC_EnableIRQ(DMA1_Stream6_IRQn);
  /* DMA2_Stream0_IRQn interrupt configuration */
  HAL_NVIC_SetPriority(DMA2_Stream0_IRQn, 0, 0);
  HAL_NVIC_EnableIRQ(DMA2_Stream0_IRQn);
  /* DMA2_Stream1_IRQn interrupt configuration */
  HAL_NVIC_SetPriority(DMA2_Stream1_IRQn, 0, 0);
  HAL_NVIC_EnableIRQ(DMA2_Stream1_IRQn);
  /* DMA2_Stream6_IRQn interrupt configuration */
  HAL_NVIC_SetPriority(DMA2_Stream6_IRQn, 0, 0);
  HAL_NVIC_EnableIRQ(DMA2_Stream6_IRQn);

}

/** Configure pins as
        * Analog
        * Input
        * Output
        * EVENT_OUT
        * EXTI
*/
static void MX_GPIO_Init(void)
{

  GPIO_InitTypeDef GPIO_InitStruct;

  /* GPIO Ports Clock Enable */
  __HAL_RCC_GPIOG_CLK_ENABLE();
  __HAL_RCC_GPIOE_CLK_ENABLE();
  __HAL_RCC_GPIOB_CLK_ENABLE();
  __HAL_RCC_GPIOD_CLK_ENABLE();
  __HAL_RCC_GPIOA_CLK_ENABLE();
  __HAL_RCC_GPIOI_CLK_ENABLE();
  __HAL_RCC_GPIOF_CLK_ENABLE();
  __HAL_RCC_GPIOK_CLK_ENABLE();
  __HAL_RCC_GPIOH_CLK_ENABLE();
  __HAL_RCC_GPIOC_CLK_ENABLE();
  __HAL_RCC_GPIOJ_CLK_ENABLE();

  /*Configure GPIO pin Output Level */
  HAL_GPIO_WritePin(GPIOG, LAMP4_Pin|LAMP2_Pin|LED1_Pin, GPIO_PIN_RESET);

  /*Configure GPIO pin Output Level */
  HAL_GPIO_WritePin(GPIOD, LED3_Pin|LED2_Pin, GPIO_PIN_RESET);

  /*Configure GPIO pin Output Level */
  HAL_GPIO_WritePin(LED4_GPIO_Port, LED4_Pin, GPIO_PIN_RESET);

  /*Configure GPIO pin Output Level */
  HAL_GPIO_WritePin(GPIOA, LAMP3_Pin|LAMP1_Pin, GPIO_PIN_RESET);

  /*Configure GPIO pin Output Level */
  HAL_GPIO_WritePin(GPIOH, GPIO_PIN_7, GPIO_PIN_RESET);

  /*Configure GPIO pins : LAMP4_Pin LAMP2_Pin LED1_Pin */
  GPIO_InitStruct.Pin = LAMP4_Pin|LAMP2_Pin|LED1_Pin;
  GPIO_InitStruct.Mode = GPIO_MODE_OUTPUT_PP;
  GPIO_InitStruct.Pull = GPIO_NOPULL;
  GPIO_InitStruct.Speed = GPIO_SPEED_FREQ_LOW;
  HAL_GPIO_Init(GPIOG, &GPIO_InitStruct);

  /*Configure GPIO pins : LED3_Pin LED2_Pin */
  GPIO_InitStruct.Pin = LED3_Pin|LED2_Pin;
  GPIO_InitStruct.Mode = GPIO_MODE_OUTPUT_PP;
  GPIO_InitStruct.Pull = GPIO_NOPULL;
  GPIO_InitStruct.Speed = GPIO_SPEED_FREQ_LOW;
  HAL_GPIO_Init(GPIOD, &GPIO_InitStruct);

  /*Configure GPIO pin : LED4_Pin */
  GPIO_InitStruct.Pin = LED4_Pin;
  GPIO_InitStruct.Mode = GPIO_MODE_OUTPUT_PP;
  GPIO_InitStruct.Pull = GPIO_NOPULL;
  GPIO_InitStruct.Speed = GPIO_SPEED_FREQ_LOW;
  HAL_GPIO_Init(LED4_GPIO_Port, &GPIO_InitStruct);

  /*Configure GPIO pins : LAMP3_Pin LAMP1_Pin */
  GPIO_InitStruct.Pin = LAMP3_Pin|LAMP1_Pin;
  GPIO_InitStruct.Mode = GPIO_MODE_OUTPUT_PP;
  GPIO_InitStruct.Pull = GPIO_NOPULL;
  GPIO_InitStruct.Speed = GPIO_SPEED_FREQ_LOW;
  HAL_GPIO_Init(GPIOA, &GPIO_InitStruct);

  /*Configure GPIO pin : PH7 */
  GPIO_InitStruct.Pin = GPIO_PIN_7;
  GPIO_InitStruct.Mode = GPIO_MODE_OUTPUT_PP;
  GPIO_InitStruct.Pull = GPIO_NOPULL;
  GPIO_InitStruct.Speed = GPIO_SPEED_FREQ_LOW;
  HAL_GPIO_Init(GPIOH, &GPIO_InitStruct);

}

/* USER CODE BEGIN 4 */

void Encoder_Init(){
	for(int i=0; i<6;i++){
		i2c[0]= 0x00;
		i2c[1]= 0x80;
		HAL_I2C_Master_Transmit(&hi2c1,EncoderAdr[i], i2c,2,10);
	}

	for(int i=0; i<6;i++){
		i2c[0]= 0x0C;
		i2c[1]= 0x00;
		i2c[2]= 0x00;
		i2c[3]= 0x10;
		i2c[4]= 0x10;
		HAL_I2C_Master_Transmit(&hi2c1,EncoderAdr[i], i2c,5,10);
	}

	for(int i=0; i<6;i++){
		i2c[0]= 0x00;
		i2c[1]= 0x10;
		HAL_I2C_Master_Transmit(&hi2c1,EncoderAdr[i], i2c,2,10);
	}

	for(int i=0; i<6;i++){
		i2c[0]= 0x14;
		i2c[1]= 0x00;
		i2c[2]= 0x00;
		i2c[3]= 0x00;
		i2c[4]= 0x01;
		HAL_I2C_Master_Transmit(&hi2c1,EncoderAdr[i], i2c,5,10);
	}
}

/* USER CODE END 4 */

void _Error_Handler(char *file, int line)
{
  while(1)
  {
  }
}

/************************ (C) COPYRIGHT STMicroelectronics *****END OF FILE****/
